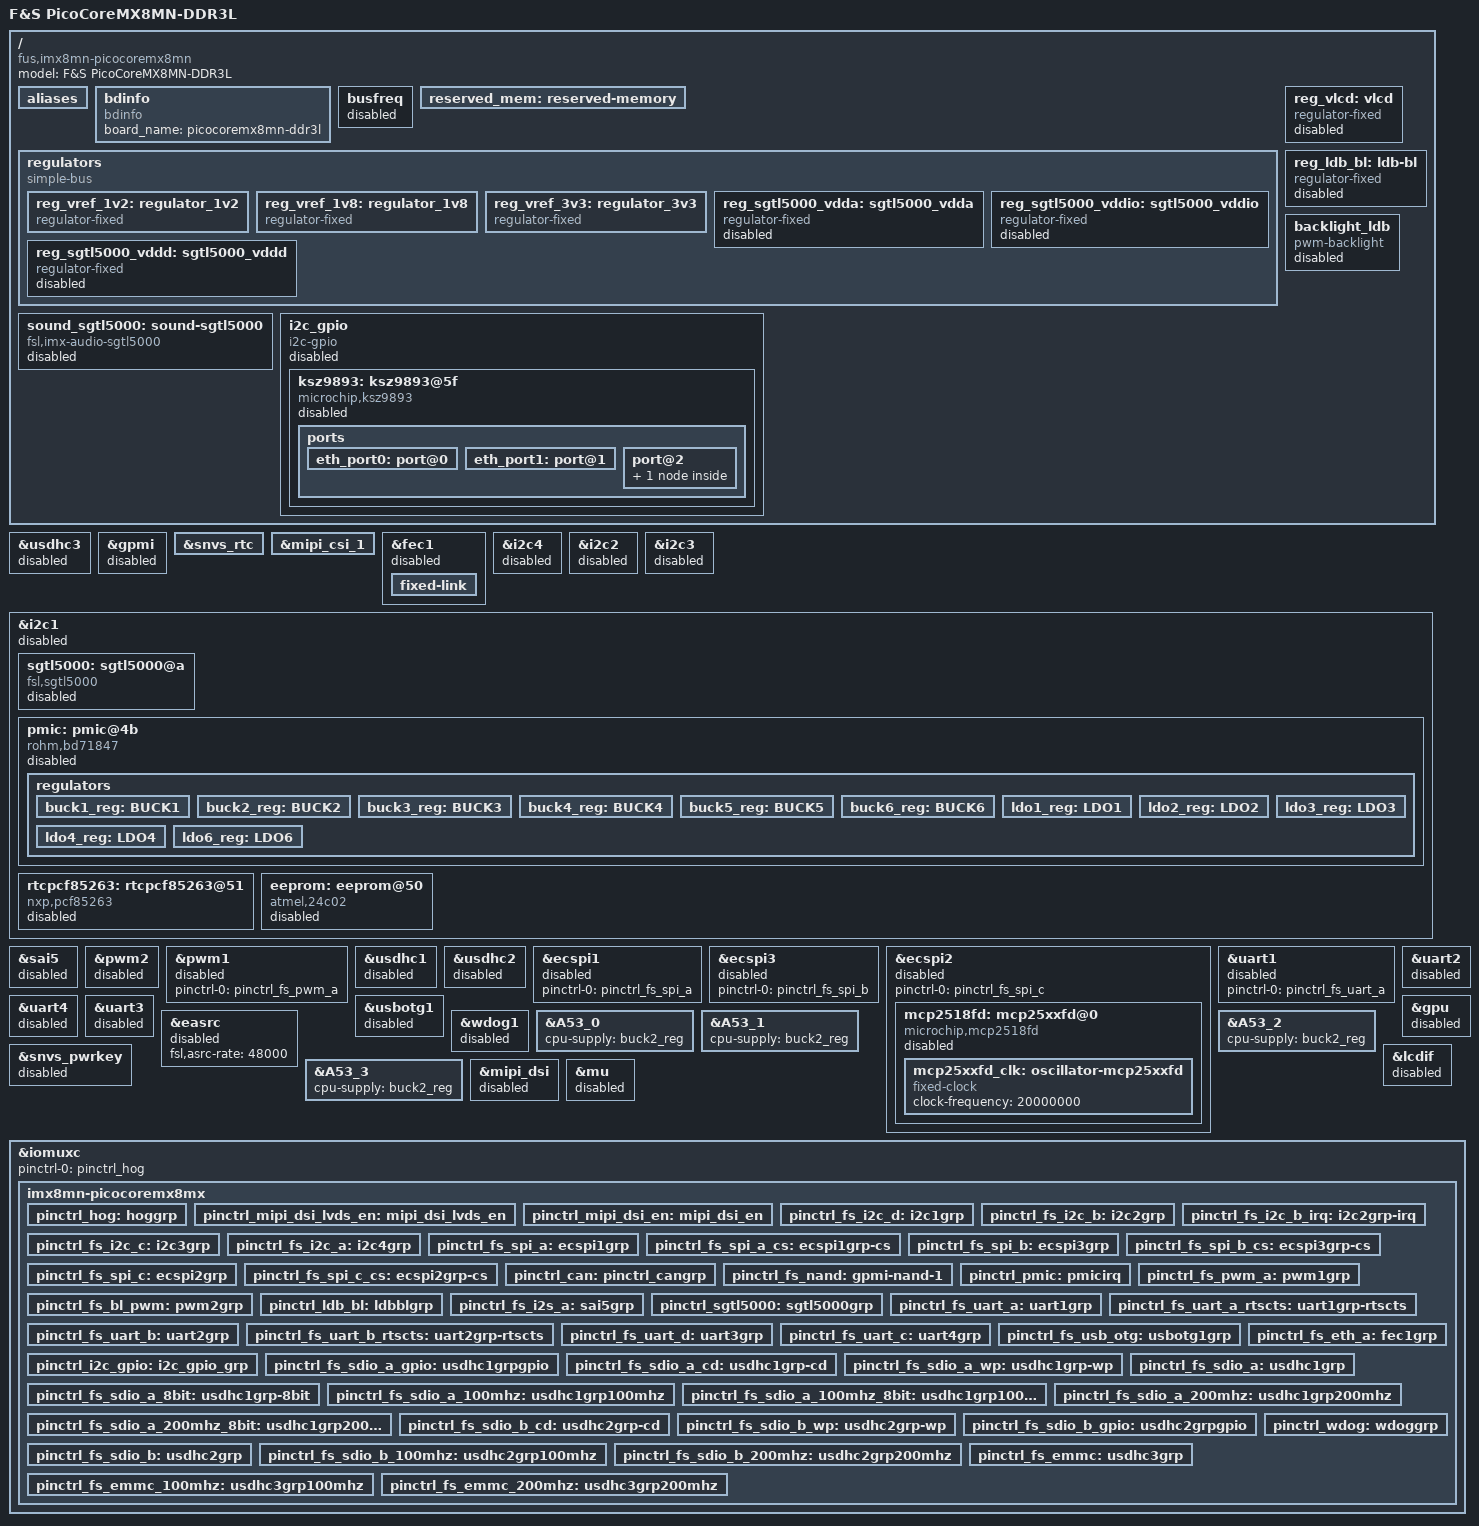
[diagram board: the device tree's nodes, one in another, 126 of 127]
/*
 * Copyright (C) 2026 F&S Elektronik Systeme GmbH
 *
 * This program is free software; you can redistribute it and/or modify
 * it under the terms of the GNU General Public License version 2 as
 * published by the Free Software Foundation.
 */

#include <dt-bindings/pwm/pwm.h>
#include <dt-bindings/rtc/nxp,pcf85263.h>
#include <dt-bindings/usb/pd.h>

/* Internal nodes */
fs_emmc: &usdhc3 {};
fs_nand: &gpmi {};
fs_rtc_soc: &snvs_rtc {};

/* External nodes */
fs_csi: &mipi_csi_1 {};
fs_eth_a: &fec1 {};
fs_i2c_a: &i2c4 {};
fs_i2c_b: &i2c2 {};
fs_i2c_c: &i2c3 {};
fs_i2c_d: &i2c1 {};
fs_i2s_a: &sai5 {};
fs_bl_pwm: &pwm2 {};
fs_pwm_a: &pwm1 {};
fs_sdio_a: &usdhc1 {};
fs_sdio_b: &usdhc2 {};
fs_spi_a: &ecspi1 {};
fs_spi_b: &ecspi3 {};
fs_spi_c: &ecspi2 {};
fs_uart_a: &uart1 {};
fs_uart_b: &uart2 {};
fs_uart_c: &uart4 {};
fs_uart_d: &uart3 {};
fs_usb_otg: &usbotg1 {};

/ {
	model = "F&S PicoCoreMX8MN-DDR3L";
	compatible = "fus,imx8mn-picocoremx8mn", "fsl,imx8mn";

	aliases {
		nand = &gpmi;
		emmc = &usdhc3;
		eeprom = &eeprom;
		mcp2518fd = &mcp2518fd;
		sgtl5000 = &sgtl5000;
		sound-sgtl5000 = &sound_sgtl5000;
		/* Due to these labels U-Boot sets mac addresses
		 * ethaddr/eth1addr to corresponding VLAN interfaces */
		ethernet = &eth_port0;
		ethernet1 = &eth_port1;
		/* Alias for gpio i2c bus. Used by bootloader. */
		i2c4 = &i2c_gpio;
	};

	bdinfo: bdinfo {
		compatible = "bdinfo";
		board_name = "picocoremx8mn-ddr3l";
	};

	/* Busfreq scaling is not working with DDR3L-RAM, keep this disabled
	 * unconditionally - it's a hardware limitation, not a feature. */
	busfreq {
		status = "disabled";
	};

	reserved_mem: reserved-memory {
		#address-cells = <2>;
		#size-cells = <2>;
		ranges;
	};

	regulators {
		compatible = "simple-bus";
		#address-cells = <1>;
		#size-cells = <0>;

		reg_vref_1v2: regulator_1v2 {
			compatible = "regulator-fixed";
			regulator-name = "vref-1V2";
			regulator-min-microvolt = <1200000>;
			regulator-max-microvolt = <1200000>;
			regulator-always-on;
		};

		reg_vref_1v8: regulator_1v8 {
			compatible = "regulator-fixed";
			regulator-name = "vref-1V8";
			regulator-min-microvolt = <1800000>;
			regulator-max-microvolt = <1800000>;
			regulator-always-on;
		};

		reg_vref_3v3: regulator_3v3 {
			compatible = "regulator-fixed";
			regulator-name = "vref-3V3";
			regulator-min-microvolt = <3300000>;
			regulator-max-microvolt = <3300000>;
			regulator-always-on;
		};

		/omit-if-no-ref/
		reg_sgtl5000_vdda: sgtl5000_vdda {
			compatible = "regulator-fixed";
			regulator-name = "VDDA-supply";
			regulator-min-microvolt = <3300000>;
			regulator-max-microvolt = <3300000>;
			regulator-always-on;
			status = "disabled";
		};

		/omit-if-no-ref/
		reg_sgtl5000_vddio: sgtl5000_vddio {
			compatible = "regulator-fixed";
			regulator-name = "VDDIO-supply";
			regulator-min-microvolt = <3300000>;
			regulator-max-microvolt = <3300000>;
			regulator-always-on;
			status = "disabled";
		};

		/omit-if-no-ref/
		reg_sgtl5000_vddd: sgtl5000_vddd {
			compatible = "regulator-fixed";
			regulator-name = "VDDD-supply";
			regulator-min-microvolt = <1500000>;
			regulator-max-microvolt = <1500000>;
			regulator-always-on;
			status = "disabled";
		};
	};

	/* only needed with a MIPI_DSI/MIPI_DSI_LVDS display attached */
	/omit-if-no-ref/
	reg_vlcd: vlcd {
		compatible = "regulator-fixed";
		regulator-name = "VLCD";
		gpio = <&gpio5 1 GPIO_ACTIVE_HIGH>;
		regulator-min-microvolt = <3300000>;
		regulator-max-microvolt = <3300000>;
		enable-active-high;
		status = "disabled";
	};

	/omit-if-no-ref/
	reg_ldb_bl: ldb-bl {
		compatible = "regulator-fixed";
		regulator-name = "ldb-bl";
		pinctrl-names = "default";
		pinctrl-0 = <&pinctrl_ldb_bl>;
		gpio = <&gpio5 3 GPIO_ACTIVE_HIGH>;
		regulator-min-microvolt = <3300000>;
		regulator-max-microvolt = <3300000>;
		enable-active-high;
		status = "disabled";
	};

	backlight_ldb: backlight_ldb {
		compatible = "pwm-backlight";
		#pwm-cells = <3>;
		pwms = <&pwm2 0 3000000 PWM_POLARITY_INVERTED>;
		power-supply = <&reg_ldb_bl>;
		brightness-levels = <0 1 5 10 18 28 41 56
				     73 92 113 137 163 192 222 255>;
		default-brightness-level = <14>;
		fb-names = "mxs-lcdif0";
		status = "disabled";
	};

	sound_sgtl5000: sound-sgtl5000 {
		#sound-dai-cells = <0>;
		compatible = "fsl,imx-audio-sgtl5000";
		model = "imx-sgtl5000";
		audio-cpu = <&sai5>;
		audio-codec = <&sgtl5000>;
		audio-asrc = <&easrc>;
		audio-routing =
			"LINE_IN", "Line In Jack",
			"Mic Jack", "Mic Bias",
			"MIC_IN", "Mic Jack",
			"Line Out Jack", "LINE_OUT",
			"Headphone Jack", "HP_OUT";
		status = "disabled";
	};

	/* Ethernet switch's internal MDIO-as-GPIO management bus, only
	 * needed together with the ksz9893 switch chip
	 * (CONFIG_PICOCOREMX8MX_NANO_ETH_I2C) */
	/omit-if-no-ref/
	i2c_gpio: i2c_gpio {
		#address-cells = <1>;
		#size-cells = <0>;
		pinctrl-names = "default";
		pinctrl-0 = <&pinctrl_i2c_gpio>;
		compatible = "i2c-gpio";
		gpios = <&gpio1 17 0 /* sda */
			 &gpio1 16 0 /* scl */
			>;
		i2c-gpio,delay-us = <2>;	/* ~100 kHz */
		status = "disabled";
	};
};

&fs_i2c_a {
	clock-frequency = <100000>;
	pinctrl-names = "default";
	pinctrl-0 = <&pinctrl_fs_i2c_a>;
	status = "disabled";
};

&fs_i2c_b {
	clock-frequency = <100000>;
	pinctrl-names = "default";
	pinctrl-0 = <&pinctrl_fs_i2c_b>, <&pinctrl_fs_i2c_b_irq>;
	status = "disabled";
};

&fs_i2c_c {
	clock-frequency = <100000>;
	pinctrl-names = "default";
	pinctrl-0 = <&pinctrl_fs_i2c_c>;
	status = "disabled";
};

/* hosts the PMIC - always on regardless of the (customer-facing) I2C_D
 * connector define, same convention as every other fsimx8mn/fsimx8mm module */
&fs_i2c_d {
	clock-frequency = <100000>;
	pinctrl-names = "default";
	pinctrl-0 = <&pinctrl_fs_i2c_d>;
	status = "disabled";

	sgtl5000: sgtl5000@a {
		#sound-dai-cells = <0>;
		compatible = "fsl,sgtl5000";
		pinctrl-names = "default";
		pinctrl-0 = <&pinctrl_sgtl5000>;
		reg = <0xa>;
		mono2both;
		clocks = <&clk IMX8MN_CLK_SAI5_ROOT>;
		VDDA-supply = <&reg_sgtl5000_vdda>;
		VDDIO-supply = <&reg_sgtl5000_vddio>;
		VDDD-supply = <&reg_sgtl5000_vddd>;
		status = "disabled";
	};

	/* PMIC */
	pmic: pmic@4b {
		compatible = "rohm,bd71847";
		reg = <0x4b>;
		pinctrl-names = "default";
		pinctrl-0 = <&pinctrl_pmic>;
		interrupt-parent = <&gpio1>;
		interrupts = <10 GPIO_ACTIVE_LOW>;
		rohm,reset-snvs-powered;

		#clock-cells = <0>;
		clocks = <&osc_32k 0>;
		clock-output-names = "clk-32k-out";
		status = "disabled";

		regulators {
			buck1_reg: BUCK1 {
				regulator-name = "BUCK1";
				regulator-min-microvolt = <700000>;
				regulator-max-microvolt = <1300000>;
				regulator-boot-on;
				regulator-always-on;
				regulator-ramp-delay = <1250>;
				rohm,dvs-run-voltage = <850000>;
				rohm,dvs-suspend-voltage = <750000>;
			};

			buck2_reg: BUCK2 {
				regulator-name = "BUCK2";
				regulator-min-microvolt = <700000>;
				regulator-max-microvolt = <1300000>;
				regulator-boot-on;
				regulator-always-on;
				regulator-ramp-delay = <1250>;
				rohm,dvs-run-voltage = <1000000>;
				rohm,dvs-idle-voltage = <900000>;
				rohm,dvs-suspend-voltage = <0>;
			};

			buck3_reg: BUCK3 {
				// BUCK5 in datasheet
				regulator-name = "BUCK3";
				regulator-min-microvolt = <700000>;
				regulator-max-microvolt = <1350000>;
				regulator-boot-on;
				regulator-always-on;
			};

			buck4_reg: BUCK4 {
				// BUCK6 in datasheet
				regulator-name = "BUCK4";
				regulator-min-microvolt = <3000000>;
				regulator-max-microvolt = <3300000>;
				regulator-boot-on;
				regulator-always-on;
			};

			buck5_reg: BUCK5 {
				// BUCK7 in datasheet
				regulator-name = "BUCK5";
				regulator-min-microvolt = <1605000>;
				regulator-max-microvolt = <1995000>;
				regulator-boot-on;
				regulator-always-on;
			};

			buck6_reg: BUCK6 {
				// BUCK8 in datasheet
				regulator-name = "BUCK6";
				regulator-min-microvolt = <800000>;
				regulator-max-microvolt = <1400000>;
				regulator-boot-on;
				regulator-always-on;
			};

			ldo1_reg: LDO1 {
				regulator-name = "LDO1";
				regulator-min-microvolt = <1600000>;
				regulator-max-microvolt = <1900000>;
				regulator-boot-on;
				regulator-always-on;
			};

			ldo2_reg: LDO2 {
				regulator-name = "LDO2";
				regulator-min-microvolt = <800000>;
				regulator-max-microvolt = <900000>;
				regulator-boot-on;
				regulator-always-on;
			};

			ldo3_reg: LDO3 {
				regulator-name = "LDO3";
				regulator-min-microvolt = <1800000>;
				regulator-max-microvolt = <3300000>;
				regulator-boot-on;
				regulator-always-on;
			};

			ldo4_reg: LDO4 {
				regulator-name = "LDO4";
				regulator-min-microvolt = <900000>;
				regulator-max-microvolt = <1800000>;
				regulator-boot-on;
				regulator-always-on;
			};

			ldo6_reg: LDO6 {
				regulator-name = "LDO6";
				regulator-min-microvolt = <900000>;
				regulator-max-microvolt = <1800000>;
				regulator-boot-on;
				regulator-always-on;
			};
		};
	};

	rtcpcf85263: rtcpcf85263@51 {
		compatible = "nxp,pcf85263";
		reg = <0x51>;
		clock-out = <PCF85263_CLK_OUT_32p768kHz>;

		quartz-load-capacitance = <PCF85263_QUARTZCAP_12p5pF>;
		quartz-drive-strength = <PCF85263_QUARTZDRIVE_LOW>;
		status = "disabled";
	};

	eeprom: eeprom@50 {
		compatible = "atmel,24c02";
		reg = <0x50>;
		pagesize = <8>;
		status = "disabled";
	};
};

&fs_pwm_a {
	pinctrl-names = "default";
	pinctrl-0 = <&pinctrl_fs_pwm_a>;
	status = "disabled";
};

&fs_bl_pwm {
	pinctrl-names = "default";
	pinctrl-0 = <&pinctrl_fs_bl_pwm>;
	#pwm-cells = <3>;
	keep-power;
	status = "disabled";
};

&fs_i2s_a {
	#sound-dai-cells = <0>;
	pinctrl-names = "default";
	pinctrl-0 = <&pinctrl_fs_i2s_a>;
	assigned-clocks = <&clk IMX8MN_CLK_SAI5>;
	assigned-clock-parents = <&clk IMX8MN_AUDIO_PLL1_OUT>;
	assigned-clock-rates = <24576000>;
	status = "disabled";
};

&easrc {
	fsl,asrc-rate = <48000>;
	status = "disabled";
};

&fs_spi_a {
	#address-cells = <1>;
	#size-cells = <0>;
	pinctrl-names = "default";
	pinctrl-0 = <&pinctrl_fs_spi_a>;
	status = "disabled";
};

&fs_spi_b {
	#address-cells = <1>;
	#size-cells = <0>;
	pinctrl-names = "default";
	pinctrl-0 = <&pinctrl_fs_spi_b>;
	status = "disabled";
};

/* either a CAN-FD chip (mcp2518fd) or a plain spidev is populated here,
 * board dts enables exactly one */
&fs_spi_c {
	#address-cells = <1>;
	#size-cells = <0>;
	pinctrl-names = "default";
	pinctrl-0 = <&pinctrl_fs_spi_c>;
	status = "disabled";

	mcp2518fd: mcp25xxfd@0 {
		compatible = "microchip,mcp2518fd";
		reg = <0>;
		pinctrl-names = "default";
		pinctrl-0 = <&pinctrl_can>;
		spi-max-frequency = <10000000>;
		interrupts-extended = <&gpio4 28 IRQ_TYPE_LEVEL_LOW>;
		clocks = <&mcp25xxfd_clk>;
		status = "disabled";

		mcp25xxfd_clk: oscillator-mcp25xxfd {
			#clock-cells = <0>;
			compatible = "fixed-clock";
			clock-frequency = <20000000>; //20MHz
		};
	};
};

&fs_uart_a { /* console */
	pinctrl-names = "default";
	pinctrl-0 = <&pinctrl_fs_uart_a>;
	status = "disabled";
};

&fs_uart_b {
	pinctrl-names = "default";
	pinctrl-0 = <&pinctrl_fs_uart_b>;
	assigned-clocks = <&clk IMX8MN_CLK_UART2>;
	assigned-clock-parents = <&clk IMX8MN_SYS_PLL1_80M>;
	status = "disabled";
};

&fs_uart_c {
	pinctrl-names = "default";
	pinctrl-0 = <&pinctrl_fs_uart_c>;
	assigned-clocks = <&clk IMX8MN_CLK_UART4>;
	assigned-clock-parents = <&clk IMX8MN_SYS_PLL1_80M>;
	status = "disabled";
};

&fs_uart_d {
	pinctrl-names = "default";
	pinctrl-0 = <&pinctrl_fs_uart_d>;
	assigned-clocks = <&clk IMX8MN_CLK_UART3>;
	assigned-clock-parents = <&clk IMX8MN_SYS_PLL1_80M>;
	status = "disabled";
};

&fs_usb_otg {
	pinctrl-names = "default";
	pinctrl-0 = <&pinctrl_fs_usb_otg>;
	picophy,pre-emp-curr-control = <3>;
	picophy,dc-vol-level-adjust = <7>;
	disable-over-current;
	status = "disabled";
};

&fs_sdio_a {
	assigned-clocks = <&clk IMX8MN_CLK_USDHC1>;
	assigned-clock-rates = <200000000>;
	pinctrl-names = "default", "state_100mhz", "state_200mhz";
	pinctrl-0 = <&pinctrl_fs_sdio_a>, <&pinctrl_fs_sdio_a_gpio>;
	pinctrl-1 = <&pinctrl_fs_sdio_a_100mhz>, <&pinctrl_fs_sdio_a_gpio>;
	pinctrl-2 = <&pinctrl_fs_sdio_a_200mhz>, <&pinctrl_fs_sdio_a_gpio>;
	bus-width = <4>;
	vmmc-supply = <&reg_vref_3v3>;
	vqmmc-supply = <&reg_vref_3v3>;
	pm-ignore-notify;
	keep-power-in-suspend;
	status = "disabled";
};

/* plain external SD_B slot - no WLAN alternative on this board */
&fs_sdio_b {
	assigned-clocks = <&clk IMX8MN_CLK_USDHC2>;
	assigned-clock-rates = <200000000>;
	pinctrl-names = "default", "state_100mhz", "state_200mhz";
	pinctrl-0 = <&pinctrl_fs_sdio_b>, <&pinctrl_fs_sdio_b_gpio>;
	pinctrl-1 = <&pinctrl_fs_sdio_b_100mhz>, <&pinctrl_fs_sdio_b_gpio>;
	pinctrl-2 = <&pinctrl_fs_sdio_b_200mhz>, <&pinctrl_fs_sdio_b_gpio>;
	bus-width = <4>;
	vmmc-supply = <&reg_vref_3v3>;
	vqmmc-supply = <&reg_vref_3v3>;
	voltage-ranges = <3300 3300>;
	no-1-8-v;
	keep-power-in-suspend;
	status = "disabled";
};

&fs_emmc {
	assigned-clocks = <&clk IMX8MN_CLK_USDHC3>;
	assigned-clock-rates = <400000000>;
	pinctrl-names = "default", "state_100mhz", "state_200mhz";
	pinctrl-0 = <&pinctrl_fs_emmc>;
	pinctrl-1 = <&pinctrl_fs_emmc_100mhz>;
	pinctrl-2 = <&pinctrl_fs_emmc_200mhz>;
	bus-width = <8>;
	non-removable;
	status = "disabled";
};

&fs_nand {
	pinctrl-names = "default";
	pinctrl-0 = <&pinctrl_fs_nand>;
	fsl,use-minimum-ecc;
	status = "disabled";
};

/* Ethernet switch chip (2 external LAN ports via ksz9893), needs the
 * i2c_gpio bitbang bus above - board dts enables both together */
&i2c_gpio {
	status = "disabled";

	ksz9893: ksz9893@5f {
		compatible = "microchip,ksz9893";
		reg = <0x5f>;
		xmii-mac-mode = <0>;
		led-gpio-phy-link = <0>;
		status = "disabled";

		ports {
			#address-cells = <1>;
			#size-cells = <0>;
			eth_port0: port@0 {
				reg = <0>;
				label = "lan1";
				local-mac-address = [00 05 51 07 55 81];
			};
			eth_port1: port@1 {
				reg = <1>;
				label = "lan2";
				local-mac-address = [00 05 51 07 55 80];
			};
			port@2 {
				reg = <2>;
				label = "cpu";
				ethernet = <&fec1>;
				phy-mode = "rgmii-txid";
				tx-internal-delay-ps = <1500>;
				rx-internal-delay-ps = <0>;
				fixed-link {
					speed = <1000>;
					full-duplex;
				};
			};
		};
	};
};

&fs_eth_a {
	pinctrl-names = "default";
	pinctrl-0 = <&pinctrl_fs_eth_a>;
	phy-mode = "rgmii-id";
	phy-reset-gpios = <&gpio1 5 GPIO_ACTIVE_LOW>;
	phy-reset-duration = <11>;
	phy-reset-post-delay = <1>;
	fsl,magic-packet;
	status = "disabled";

	fixed-link {
		speed = <1000>;
		full-duplex;
	};
};

&wdog1 {
	pinctrl-names = "default";
	pinctrl-0 = <&pinctrl_wdog>;
	fsl,ext-reset-output;
	status = "disabled";
};

&A53_0 {
	cpu-supply = <&buck2_reg>;
};

&A53_1 {
	cpu-supply = <&buck2_reg>;
};

&A53_2 {
	cpu-supply = <&buck2_reg>;
};

&A53_3 {
	cpu-supply = <&buck2_reg>;
};

&gpu {
	status = "disabled";
};

&snvs_pwrkey {
	status = "disabled";
};

&lcdif {
	status = "disabled";
};

&mipi_dsi {
	status = "disabled";
};

/* CM4/remoteproc was never implemented for this board (old file only had a
 * dead #if 0 rpmsg-audio TODO) - mu is gated the same way as the mx8mm
 * sibling for consistency, but no imx8mm-cm4-style node exists to enable
 * alongside it. */
&mu {
	status = "disabled";
};

&iomuxc {
	pinctrl-names = "default";
	pinctrl-0 = <&pinctrl_hog>;

	imx8mn-picocoremx8mx {
		/* Pin configs that don't belong anywhere else */
		pinctrl_hog: hoggrp {
			fsl,pins = <
				/* SEC CHIP */
				MX8MN_IOMUXC_GPIO1_IO09_GPIO1_IO9	0x00104
			>;
		};

		pinctrl_mipi_dsi_lvds_en: mipi_dsi_lvds_en {
			fsl,pins = <
				/* LVDS STBY / TC358764 STBY */
				MX8MN_IOMUXC_GPIO1_IO04_GPIO1_IO4	0x00016
				/* LVDS RESET / TC358764 RST */
				MX8MN_IOMUXC_GPIO1_IO08_GPIO1_IO8	0x00016
				/* Use MIP-DSI CLK as source by default.
				 * For EXTCLK use the following setting
				 * in your display DTS
				 */
//				MX8MN_IOMUXC_GPIO1_IO15_CCMSRCGPCMIX_CLKO2	0x00059
				MX8MN_IOMUXC_GPIO1_IO15_GPIO1_IO15	0x00016
			>;
		};

		pinctrl_mipi_dsi_en: mipi_dsi_en {
			fsl,pins = <
				/* MIPI_RSTn */
				MX8MN_IOMUXC_GPIO1_IO01_GPIO1_IO1	0x00104
			>;
		};

		pinctrl_fs_i2c_d: i2c1grp {
			fsl,pins = <
				MX8MN_IOMUXC_I2C1_SCL_I2C1_SCL		0x400001c3
				MX8MN_IOMUXC_I2C1_SDA_I2C1_SDA		0x400001c3
			>;
		};

		pinctrl_fs_i2c_b: i2c2grp {
			fsl,pins = <
				MX8MN_IOMUXC_I2C2_SCL_I2C2_SCL		0x400001c3
				MX8MN_IOMUXC_I2C2_SDA_I2C2_SDA		0x400001c3
			>;
		};

		/* I2C_B_IRQn -> Touch often needs hysteresis */
		pinctrl_fs_i2c_b_irq: i2c2grp-irq {
			fsl,pins = <
				MX8MN_IOMUXC_SAI3_MCLK_GPIO5_IO2	0x00144
			>;
		};

		pinctrl_fs_i2c_c: i2c3grp {
			fsl,pins = <
				MX8MN_IOMUXC_I2C3_SCL_I2C3_SCL		0x400001c3
				MX8MN_IOMUXC_I2C3_SDA_I2C3_SDA		0x400001c3
			>;
		};

		pinctrl_fs_i2c_a: i2c4grp {
			fsl,pins = <
				MX8MN_IOMUXC_I2C4_SCL_I2C4_SCL		0x400001c3
				MX8MN_IOMUXC_I2C4_SDA_I2C4_SDA		0x400001c3
			>;
		};

		pinctrl_fs_spi_a: ecspi1grp {
			fsl,pins = <
				MX8MN_IOMUXC_ECSPI1_SCLK_ECSPI1_SCLK	0x00082
				MX8MN_IOMUXC_ECSPI1_MOSI_ECSPI1_MOSI	0x00082
				MX8MN_IOMUXC_ECSPI1_MISO_ECSPI1_MISO	0x00082
			>;
		};

		pinctrl_fs_spi_a_cs: ecspi1grp-cs {
			fsl,pins = <
				MX8MN_IOMUXC_ECSPI1_SS0_GPIO5_IO9	0x40000
			>;
		};

		pinctrl_fs_spi_b: ecspi3grp {
			fsl,pins = <
				MX8MN_IOMUXC_UART1_RXD_ECSPI3_SCLK	0x00082
				MX8MN_IOMUXC_UART1_TXD_ECSPI3_MOSI	0x00082
				MX8MN_IOMUXC_UART2_RXD_ECSPI3_MISO	0x00082
			>;
		};

		pinctrl_fs_spi_b_cs: ecspi3grp-cs {
			fsl,pins = <
				MX8MN_IOMUXC_UART2_TXD_GPIO5_IO25	0x40000
			>;
		};

		pinctrl_fs_spi_c: ecspi2grp {
			fsl,pins = <
				MX8MN_IOMUXC_ECSPI2_SCLK_ECSPI2_SCLK	0x00082
				MX8MN_IOMUXC_ECSPI2_MOSI_ECSPI2_MOSI	0x00082
				MX8MN_IOMUXC_ECSPI2_MISO_ECSPI2_MISO	0x00082
			>;
		};

		pinctrl_fs_spi_c_cs: ecspi2grp-cs {
			fsl,pins = <
				MX8MN_IOMUXC_ECSPI2_SS0_GPIO5_IO13	0x00144
			>;
		};

		pinctrl_can: pinctrl_cangrp {
			fsl,pins = <
				/* CAN_CLK0/SOF */
				MX8MN_IOMUXC_SAI2_MCLK_GPIO4_IO27	0x00104
				/* CAN_INTn */
				MX8MN_IOMUXC_SAI3_RXFS_GPIO4_IO28	0x00019
				/* CAN_INT0n */
				MX8MN_IOMUXC_SAI2_TXC_GPIO4_IO25	0x00104
				/* CAN_INT1n */
				MX8MN_IOMUXC_SAI2_TXD0_GPIO4_IO26	0x00104
			>;
		};

		pinctrl_fs_nand: gpmi-nand-1 {
			fsl,pins = <
				MX8MN_IOMUXC_NAND_ALE_RAWNAND_ALE	0x00096
				MX8MN_IOMUXC_NAND_CE0_B_RAWNAND_CE0_B	0x00096
				MX8MN_IOMUXC_NAND_CLE_RAWNAND_CLE	0x00096
				MX8MN_IOMUXC_NAND_DATA00_RAWNAND_DATA00	0x00096
				MX8MN_IOMUXC_NAND_DATA01_RAWNAND_DATA01	0x00096
				MX8MN_IOMUXC_NAND_DATA02_RAWNAND_DATA02	0x00096
				MX8MN_IOMUXC_NAND_DATA03_RAWNAND_DATA03	0x00096
				MX8MN_IOMUXC_NAND_DATA04_RAWNAND_DATA04	0x00096
				MX8MN_IOMUXC_NAND_DATA05_RAWNAND_DATA05	0x00096
				MX8MN_IOMUXC_NAND_DATA06_RAWNAND_DATA06	0x00096
				MX8MN_IOMUXC_NAND_DATA07_RAWNAND_DATA07	0x00096
				MX8MN_IOMUXC_NAND_RE_B_RAWNAND_RE_B	0x00096
				MX8MN_IOMUXC_NAND_READY_B_RAWNAND_READY_B	0x00056
				MX8MN_IOMUXC_NAND_WE_B_RAWNAND_WE_B	0x00096
				MX8MN_IOMUXC_NAND_WP_B_RAWNAND_WP_B	0x00096
			>;
		};

		pinctrl_pmic: pmicirq {
			fsl,pins = <
				MX8MN_IOMUXC_GPIO1_IO10_GPIO1_IO10	0x00041
			>;
		};

		pinctrl_fs_pwm_a: pwm1grp {
			fsl,pins = <
				MX8MN_IOMUXC_SPDIF_EXT_CLK_PWM1_OUT	0x00104
			>;
		};

		pinctrl_fs_bl_pwm: pwm2grp {
			fsl,pins = <
				MX8MN_IOMUXC_SPDIF_RX_PWM2_OUT		0x00104
			>;
		};

		pinctrl_ldb_bl: ldbblgrp {
			fsl,pins = <
				MX8MN_IOMUXC_SPDIF_TX_GPIO5_IO3		0x00104
			>;
		};

		pinctrl_fs_i2s_a: sai5grp {
			fsl,pins = <
				MX8MN_IOMUXC_SAI5_RXD1_SAI5_TX_SYNC	0x000d6
				MX8MN_IOMUXC_SAI5_RXD2_SAI5_TX_BCLK	0x000d6
				MX8MN_IOMUXC_SAI5_RXD3_SAI5_TX_DATA0	0x000d6
				MX8MN_IOMUXC_SAI5_RXD0_SAI5_RX_DATA0	0x000d6
			>;
		};

		pinctrl_sgtl5000: sgtl5000grp {
			fsl,pins = <
				MX8MN_IOMUXC_SAI5_MCLK_SAI5_MCLK	0x000d6
			>;
		};

		pinctrl_fs_uart_a: uart1grp {
			fsl,pins = <
				MX8MN_IOMUXC_SAI2_RXC_UART1_DCE_RX	0x00140
				MX8MN_IOMUXC_SAI2_RXFS_UART1_DCE_TX	0x00140
			>;
		};

		pinctrl_fs_uart_a_rtscts: uart1grp-rtscts {
			fsl,pins = <
				/* CTS */
				MX8MN_IOMUXC_SAI2_RXD0_UART1_DCE_RTS_B	0x00140
				/* RTS */
				MX8MN_IOMUXC_SAI2_TXFS_UART1_DCE_CTS_B	0x00140
			>;
		};

		/* debug output */
		pinctrl_fs_uart_b: uart2grp {
			fsl,pins = <
				MX8MN_IOMUXC_SAI3_TXFS_UART2_DCE_RX	0x00140
				MX8MN_IOMUXC_SAI3_TXC_UART2_DCE_TX	0x00140
			>;
		};

		pinctrl_fs_uart_b_rtscts: uart2grp-rtscts {
			fsl,pins = <
				/* UART_B_CTS */
				MX8MN_IOMUXC_SAI3_RXC_UART2_DCE_CTS_B	0x00140
				/* UART_B_RTS */
				MX8MN_IOMUXC_SAI3_RXD_UART2_DCE_RTS_B	0x00140
			>;
		};

		pinctrl_fs_uart_d: uart3grp {
			fsl,pins = <
				MX8MN_IOMUXC_UART3_RXD_UART3_DCE_RX	0x00140
				MX8MN_IOMUXC_UART3_TXD_UART3_DCE_TX	0x00140
			>;
		};

		pinctrl_fs_uart_c: uart4grp {
			fsl,pins = <
				MX8MN_IOMUXC_UART4_RXD_UART4_DCE_RX	0x00140
				MX8MN_IOMUXC_UART4_TXD_UART4_DCE_TX	0x00140
			>;
		};

		pinctrl_fs_usb_otg: usbotg1grp {
			fsl,pins = <
				MX8MN_IOMUXC_GPIO1_IO12_USB1_OTG_PWR	0x00144
			>;
		};

		pinctrl_fs_eth_a: fec1grp {
			fsl,pins = <
				MX8MN_IOMUXC_ENET_TD3_ENET1_RGMII_TD3	0x0001f
				MX8MN_IOMUXC_ENET_TD2_ENET1_RGMII_TD2	0x0001f
				MX8MN_IOMUXC_ENET_TD1_ENET1_RGMII_TD1	0x0001f
				MX8MN_IOMUXC_ENET_TD0_ENET1_RGMII_TD0	0x0001f
				MX8MN_IOMUXC_ENET_RD3_ENET1_RGMII_RD3	0x00091
				MX8MN_IOMUXC_ENET_RD2_ENET1_RGMII_RD2	0x00091
				MX8MN_IOMUXC_ENET_RD1_ENET1_RGMII_RD1	0x00091
				MX8MN_IOMUXC_ENET_RD0_ENET1_RGMII_RD0	0x001D1
				MX8MN_IOMUXC_ENET_TXC_ENET1_RGMII_TXC	0x0001f
				MX8MN_IOMUXC_ENET_RXC_ENET1_RGMII_RXC	0x00091
				MX8MN_IOMUXC_ENET_RX_CTL_ENET1_RGMII_RX_CTL	0x00091
				MX8MN_IOMUXC_ENET_TX_CTL_ENET1_RGMII_TX_CTL	0x0001f
				/* ETH_SW_RST */
				MX8MN_IOMUXC_GPIO1_IO05_GPIO1_IO5	0x00019
				/* ETH_SW_INTn */
				MX8MN_IOMUXC_GPIO1_IO11_GPIO1_IO11	0x00064
				/* ETH_SW_PMEn */
				MX8MN_IOMUXC_GPIO1_IO00_GPIO1_IO0	0x00004
			>;
		};

		pinctrl_i2c_gpio: i2c_gpio_grp {
			fsl,pins = <
				MX8MN_IOMUXC_ENET_MDC_GPIO1_IO16	0x000001c3
				MX8MN_IOMUXC_ENET_MDIO_GPIO1_IO17	0x000001c3
			>;
		};

		pinctrl_fs_sdio_a_gpio: usdhc1grpgpio {
			fsl,pins = <
				/* SD_A_VSEL, 3,3V = PD, 1.8 = PU */
				MX8MN_IOMUXC_GPIO1_IO03_USDHC1_VSELECT	0x001d0
				/* RESET, high active */
				MX8MN_IOMUXC_SD1_RESET_B_USDHC1_RESET_B	0x00041
			>;
		};

		pinctrl_fs_sdio_a_cd: usdhc1grp-cd {
			fsl,pins = <
				MX8MN_IOMUXC_GPIO1_IO06_GPIO1_IO6	0x001c4
			>;
		};

		pinctrl_fs_sdio_a_wp: usdhc1grp-wp {
			fsl,pins = <
				MX8MN_IOMUXC_GPIO1_IO07_GPIO1_IO7	0x001c4
			>;
		};

		pinctrl_fs_sdio_a: usdhc1grp {
			fsl,pins = <
				MX8MN_IOMUXC_SD1_CLK_USDHC1_CLK		0x00190
				MX8MN_IOMUXC_SD1_CMD_USDHC1_CMD		0x001d0
				MX8MN_IOMUXC_SD1_DATA0_USDHC1_DATA0	0x001d0
				MX8MN_IOMUXC_SD1_DATA1_USDHC1_DATA1	0x001d0
				MX8MN_IOMUXC_SD1_DATA2_USDHC1_DATA2	0x001d0
				MX8MN_IOMUXC_SD1_DATA3_USDHC1_DATA3	0x001d0
			>;
		};

		pinctrl_fs_sdio_a_8bit: usdhc1grp-8bit {
			fsl,pins = <
				MX8MN_IOMUXC_SD1_CLK_USDHC1_CLK		0x00190
				MX8MN_IOMUXC_SD1_CMD_USDHC1_CMD		0x001d0
				MX8MN_IOMUXC_SD1_DATA0_USDHC1_DATA0	0x001d0
				MX8MN_IOMUXC_SD1_DATA1_USDHC1_DATA1	0x001d0
				MX8MN_IOMUXC_SD1_DATA2_USDHC1_DATA2	0x001d0
				MX8MN_IOMUXC_SD1_DATA3_USDHC1_DATA3	0x001d0
				MX8MN_IOMUXC_SD1_DATA4_USDHC1_DATA4	0x001d0
				MX8MN_IOMUXC_SD1_DATA5_USDHC1_DATA5	0x001d0
				MX8MN_IOMUXC_SD1_DATA6_USDHC1_DATA6	0x001d0
				MX8MN_IOMUXC_SD1_DATA7_USDHC1_DATA7	0x001d0
			>;
		};

		pinctrl_fs_sdio_a_100mhz: usdhc1grp100mhz {
			fsl,pins = <
				MX8MN_IOMUXC_SD1_CLK_USDHC1_CLK		0x00194
				MX8MN_IOMUXC_SD1_CMD_USDHC1_CMD		0x001d4
				MX8MN_IOMUXC_SD1_DATA0_USDHC1_DATA0	0x001d4
				MX8MN_IOMUXC_SD1_DATA1_USDHC1_DATA1	0x001d4
				MX8MN_IOMUXC_SD1_DATA2_USDHC1_DATA2	0x001d4
				MX8MN_IOMUXC_SD1_DATA3_USDHC1_DATA3	0x001d4
			>;
		};

		pinctrl_fs_sdio_a_100mhz_8bit: usdhc1grp100mhz-8bit {
			fsl,pins = <
				MX8MN_IOMUXC_SD1_CLK_USDHC1_CLK		0x00194
				MX8MN_IOMUXC_SD1_CMD_USDHC1_CMD		0x001d4
				MX8MN_IOMUXC_SD1_DATA0_USDHC1_DATA0	0x001d4
				MX8MN_IOMUXC_SD1_DATA1_USDHC1_DATA1	0x001d4
				MX8MN_IOMUXC_SD1_DATA2_USDHC1_DATA2	0x001d4
				MX8MN_IOMUXC_SD1_DATA3_USDHC1_DATA3	0x001d4
				MX8MN_IOMUXC_SD1_DATA4_USDHC1_DATA4	0x001d4
				MX8MN_IOMUXC_SD1_DATA5_USDHC1_DATA5	0x001d4
				MX8MN_IOMUXC_SD1_DATA6_USDHC1_DATA6	0x001d4
				MX8MN_IOMUXC_SD1_DATA7_USDHC1_DATA7	0x001d4
			>;
		};

		pinctrl_fs_sdio_a_200mhz: usdhc1grp200mhz {
			fsl,pins = <
				MX8MN_IOMUXC_SD1_CLK_USDHC1_CLK		0x00196
				MX8MN_IOMUXC_SD1_CMD_USDHC1_CMD		0x001d6
				MX8MN_IOMUXC_SD1_DATA0_USDHC1_DATA0	0x001d6
				MX8MN_IOMUXC_SD1_DATA1_USDHC1_DATA1	0x001d6
				MX8MN_IOMUXC_SD1_DATA2_USDHC1_DATA2	0x001d6
				MX8MN_IOMUXC_SD1_DATA3_USDHC1_DATA3	0x001d6
			>;
		};

		pinctrl_fs_sdio_a_200mhz_8bit: usdhc1grp200mhz-8bit {
			fsl,pins = <
				MX8MN_IOMUXC_SD1_CLK_USDHC1_CLK		0x00196
				MX8MN_IOMUXC_SD1_CMD_USDHC1_CMD		0x001d6
				MX8MN_IOMUXC_SD1_DATA0_USDHC1_DATA0	0x001d6
				MX8MN_IOMUXC_SD1_DATA1_USDHC1_DATA1	0x001d6
				MX8MN_IOMUXC_SD1_DATA2_USDHC1_DATA2	0x001d6
				MX8MN_IOMUXC_SD1_DATA3_USDHC1_DATA3	0x001d6
				MX8MN_IOMUXC_SD1_DATA4_USDHC1_DATA4	0x001d6
				MX8MN_IOMUXC_SD1_DATA5_USDHC1_DATA5	0x001d6
				MX8MN_IOMUXC_SD1_DATA6_USDHC1_DATA6	0x001d6
				MX8MN_IOMUXC_SD1_DATA7_USDHC1_DATA7	0x001d6
			>;
		};

		pinctrl_fs_sdio_b_cd: usdhc2grp-cd {
			fsl,pins = <
				MX8MN_IOMUXC_SD2_CD_B_GPIO2_IO12	0x001c4
			>;
		};

		pinctrl_fs_sdio_b_wp: usdhc2grp-wp {
			fsl,pins = <
				MX8MN_IOMUXC_SD2_WP_GPIO2_IO20		0x001c4
			>;
		};

		pinctrl_fs_sdio_b_gpio: usdhc2grpgpio {
			fsl,pins = <
				/* SD_B_RST */
				MX8MN_IOMUXC_SD2_RESET_B_USDHC2_RESET_B	0x00041
			>;
		};

		pinctrl_fs_sdio_b: usdhc2grp {
			fsl,pins = <
				MX8MN_IOMUXC_SD2_CLK_USDHC2_CLK		0x00190
				MX8MN_IOMUXC_SD2_CMD_USDHC2_CMD		0x001d0
				MX8MN_IOMUXC_SD2_DATA0_USDHC2_DATA0	0x001d0
				MX8MN_IOMUXC_SD2_DATA1_USDHC2_DATA1	0x001d0
				MX8MN_IOMUXC_SD2_DATA2_USDHC2_DATA2	0x001d0
				MX8MN_IOMUXC_SD2_DATA3_USDHC2_DATA3	0x001d0
			>;
		};

		pinctrl_fs_sdio_b_100mhz: usdhc2grp100mhz {
			fsl,pins = <
				MX8MN_IOMUXC_SD2_CLK_USDHC2_CLK		0x00194
				MX8MN_IOMUXC_SD2_CMD_USDHC2_CMD		0x001d4
				MX8MN_IOMUXC_SD2_DATA0_USDHC2_DATA0	0x001d4
				MX8MN_IOMUXC_SD2_DATA1_USDHC2_DATA1	0x001d4
				MX8MN_IOMUXC_SD2_DATA2_USDHC2_DATA2	0x001d4
				MX8MN_IOMUXC_SD2_DATA3_USDHC2_DATA3	0x001d4
			>;
		};

		pinctrl_fs_sdio_b_200mhz: usdhc2grp200mhz {
			fsl,pins = <
				MX8MN_IOMUXC_SD2_CLK_USDHC2_CLK		0x00196
				MX8MN_IOMUXC_SD2_CMD_USDHC2_CMD		0x001d6
				MX8MN_IOMUXC_SD2_DATA0_USDHC2_DATA0	0x001d6
				MX8MN_IOMUXC_SD2_DATA1_USDHC2_DATA1	0x001d6
				MX8MN_IOMUXC_SD2_DATA2_USDHC2_DATA2	0x001d6
				MX8MN_IOMUXC_SD2_DATA3_USDHC2_DATA3	0x001d6
			>;
		};

		pinctrl_fs_emmc: usdhc3grp {
			fsl,pins = <
				MX8MN_IOMUXC_NAND_WE_B_USDHC3_CLK	0x00190
				MX8MN_IOMUXC_NAND_WP_B_USDHC3_CMD	0x001d0
				MX8MN_IOMUXC_NAND_DATA04_USDHC3_DATA0	0x001d0
				MX8MN_IOMUXC_NAND_DATA05_USDHC3_DATA1	0x001d0
				MX8MN_IOMUXC_NAND_DATA06_USDHC3_DATA2	0x001d0
				MX8MN_IOMUXC_NAND_DATA07_USDHC3_DATA3	0x001d0
				MX8MN_IOMUXC_NAND_RE_B_USDHC3_DATA4	0x001d0
				MX8MN_IOMUXC_NAND_CE2_B_USDHC3_DATA5	0x001d0
				MX8MN_IOMUXC_NAND_CE3_B_USDHC3_DATA6	0x001d0
				MX8MN_IOMUXC_NAND_CLE_USDHC3_DATA7	0x001d0
				MX8MN_IOMUXC_NAND_CE1_B_USDHC3_STROBE 	0x00190
				/* NAND READY -> RESET */
				MX8MN_IOMUXC_NAND_READY_B_USDHC3_RESET_B	0x00144
			>;
		};

		pinctrl_fs_emmc_100mhz: usdhc3grp100mhz {
			fsl,pins = <
				MX8MN_IOMUXC_NAND_WE_B_USDHC3_CLK	0x00194
				MX8MN_IOMUXC_NAND_WP_B_USDHC3_CMD	0x001d4
				MX8MN_IOMUXC_NAND_DATA04_USDHC3_DATA0	0x001d4
				MX8MN_IOMUXC_NAND_DATA05_USDHC3_DATA1	0x001d4
				MX8MN_IOMUXC_NAND_DATA06_USDHC3_DATA2	0x001d4
				MX8MN_IOMUXC_NAND_DATA07_USDHC3_DATA3	0x001d4
				MX8MN_IOMUXC_NAND_RE_B_USDHC3_DATA4	0x001d4
				MX8MN_IOMUXC_NAND_CE2_B_USDHC3_DATA5	0x001d4
				MX8MN_IOMUXC_NAND_CE3_B_USDHC3_DATA6	0x001d4
				MX8MN_IOMUXC_NAND_CLE_USDHC3_DATA7	0x001d4
				MX8MN_IOMUXC_NAND_CE1_B_USDHC3_STROBE 	0x00194
				/* NAND READY -> RESET */
				MX8MN_IOMUXC_NAND_READY_B_USDHC3_RESET_B	0x00144
			>;
		};

		pinctrl_fs_emmc_200mhz: usdhc3grp200mhz {
			fsl,pins = <
				MX8MN_IOMUXC_NAND_WE_B_USDHC3_CLK	0x00196
				MX8MN_IOMUXC_NAND_WP_B_USDHC3_CMD	0x001d6
				MX8MN_IOMUXC_NAND_DATA04_USDHC3_DATA0	0x001d6
				MX8MN_IOMUXC_NAND_DATA05_USDHC3_DATA1	0x001d6
				MX8MN_IOMUXC_NAND_DATA06_USDHC3_DATA2	0x001d6
				MX8MN_IOMUXC_NAND_DATA07_USDHC3_DATA3	0x001d6
				MX8MN_IOMUXC_NAND_RE_B_USDHC3_DATA4	0x001d6
				MX8MN_IOMUXC_NAND_CE2_B_USDHC3_DATA5	0x001d6
				MX8MN_IOMUXC_NAND_CE3_B_USDHC3_DATA6	0x001d6
				MX8MN_IOMUXC_NAND_CLE_USDHC3_DATA7	0x001d6
				MX8MN_IOMUXC_NAND_CE1_B_USDHC3_STROBE 	0x00196
				/* NAND READY -> RESET */
				MX8MN_IOMUXC_NAND_READY_B_USDHC3_RESET_B	0x00144
			>;
		};

		pinctrl_wdog: wdoggrp {
			fsl,pins = <
				MX8MN_IOMUXC_GPIO1_IO02_WDOG1_WDOG_B	0x000c6
			>;
		};
	};
};
